# STM32MP23_CM33 register map
File version: 1.2
CPU: CM33 r0p1, little endian, MPU, FPU, vendor SysTick, 8 interrupt priority bits
Registers are 32-bit, read-write, reset 0x0 unless marked. A register's access mark holds for its fields unless they carry their own. Offsets are from the block's base; [hi:lo] are bit positions; {n}, {i} and the like mark numbered series.

## SPDIFRX — SPDIFRX address block description
Base 0x400D0000
Same registers: SPDIFRX_S 0x500D0000
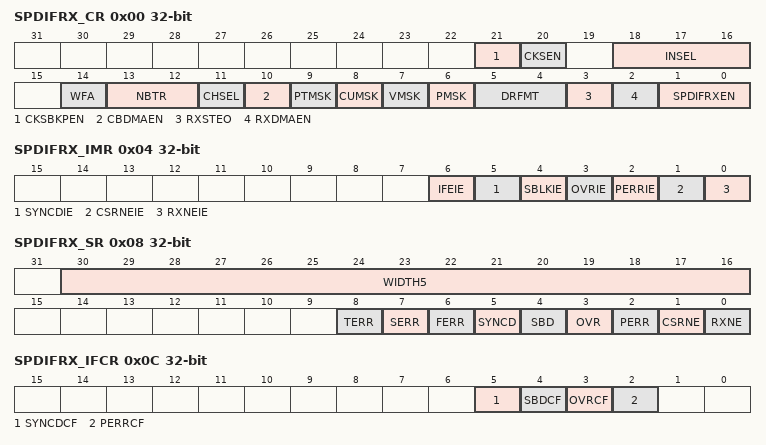
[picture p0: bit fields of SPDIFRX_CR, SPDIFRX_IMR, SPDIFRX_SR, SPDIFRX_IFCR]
0x00 SPDIFRX_CR — SPDIFRX control register
  [21] CKSBKPEN — Backup symbol clock enable This bit is set/reset by software.
    1=The SPDIFRX generates a backup symbol clock if CKSEN = 1; 0=The SPDIFRX does not generate a backup symbol clock
  [20] CKSEN — Symbol clock enable This bit is set/reset by software.
    1=The SPDIFRX generates a symbol clock; 0=The SPDIFRX does not generate a symbol clock
  [18:16] INSEL — SPDIFRX input selection other: reserved
    {v}=SPDIFRX_IN{v} selected (v=0..3)
  [14] WFA — Wait for activitysup(1)/sup This bit is set/reset by software.
    1=The SPDIFRX waits for activity on SPDIFRX_IN line (4 transitions) before performing the synchronization; 0=The SPDIFRX does not wait for activity on SPDIFRX_IN line before performing the synchronization
  [13:12] NBTR — Maximum allowed re-tries during synchronization phasesup(1)/sup
    0=No re-try is allowed (only one attempt); 1=3 re-tries allowed; 2=15 re-tries allowed; 3=63 re-tries allowed
  [11] CHSEL — Channel selectionsup(1)/sup This bit is set/reset by software.
    1=The control flow takes the channel status from channel B; 0=The control flow takes the channel status from channel A
  [10] CBDMAEN — Control buffer DMA enable for control flowsup(1)/sup This bit is set/reset by software. Note: When this bit is set, the DMA request is made whenever the CSRNE flag is set.
    1=DMA mode is enabled for reception of channel status and used data information; 0=DMA mode is disabled for reception of channel status and used data information
  [9] PTMSK — Mask of preamble type bitssup(1)/sup This bit is set/reset by software.
    1=The preamble type bits are not copied into the SPDIFRX_FMTx_DR, zeros are written instead; 0=The preamble type bits are copied into the SPDIFRX_FMTx_DR
  [8] CUMSK — Mask of channel status and user bitssup(1)/sup This bit is set/reset by software.
    1=The channel status and user bits are not copied into the SPDIFRX_FMTx_DR, zeros are written instead; 0=The channel status and user bits are copied into the SPDIFRX_FMTx_DR
  [7] VMSK — Mask of validity bitsup(1)/sup This bit is set/reset by software.
    1=The validity bit is not copied into the SPDIFRX_FMTx_DR, a zero is written instead; 0=The validity bit is copied into the SPDIFRX_FMTx_DR
  [6] PMSK — Mask parity error bitsup(1)/sup This bit is set/reset by software.
    1=The parity error bit is not copied into the SPDIFRX_FMTx_DR, a zero is written instead; 0=The parity error bit is copied into the SPDIFRX_FMTx_DR
  [5:4] DRFMT — RX data formatsup(1)/sup This bit is set/reset by software.
    2=Data sample are packed by setting two 16-bit sample into a 32-bit word; 1=Data samples are aligned in the left (MSB); 0=Data samples are aligned in the right (LSB)
  [3] RXSTEO — Stereo modesup(1)/sup This bit is set/reset by software. Note: This bit is used in case of overrun situation in order to handle misalignment.
    1=The peripheral is in stereo mode; 0=The peripheral is in mono mode
  [2] RXDMAEN — Receiver DMA enable for data flowsup(1)/sup This bit is set/reset by software. Note: When this bit is set, the DMA request is made whenever the RXNE flag is set.
    1=DMA mode is enabled for reception; 0=DMA mode is disabled for reception
  [1:0] SPDIFRXEN — Peripheral block enablesup(1)/sup This field is modified by software. It must be used to change the peripheral phase among the three possible states: STATE_IDLE, STATE_SYNC and STATE_RCV. It is not possible to transition from STATE_RCV to STATE_SYNC, the user must first go the STATE_IDLE. Note: it is possible to transition from STATE_IDLE to STATE_RCV: in that case the peripheral transitions from STATE_IDLE to STATE_SYNC and as soon as the synchronization is performed goes to STATE_RCV.
    0=Disable SPDIFRX (STATE_IDLE); 1=Enable SPDIFRX synchronization only; 3=Enable SPDIF receiver
0x04 SPDIFRX_IMR — SPDIFRX interrupt mask register
  [6] IFEIE — Serial interface error interrupt enable This bit is set and cleared by software.
    0=Interrupt is inhibited; 1=A SPDIFRX interface interrupt is generated whenever SERR = 1, TERR = 1, or FERR = 1 in theSPDIFRX_SR register
  [5] SYNCDIE — Synchronization done This bit is set and cleared by software.
    0=Interrupt is inhibited; 1=A SPDIFRX interface interrupt is generated whenever SYNCD = 1 in the SPDIFRX_SR register
  [4] SBLKIE — Synchronization block detected interrupt enable This bit is set and cleared by software.
    0=Interrupt is inhibited; 1=A SPDIFRX interface interrupt is generated whenever SBD = 1 in the SPDIFRX_SR register
  [3] OVRIE — Overrun error interrupt enable This bit is set and cleared by software.
    0=Interrupt is inhibited; 1=A SPDIFRX interface interrupt is generated whenever OVR=1 in the SPDIFRX_SR register
  [2] PERRIE — Parity error interrupt enable This bit is set and cleared by software.
    0=Interrupt is inhibited; 1=A SPDIFRX interface interrupt is generated whenever PERR=1 in the SPDIFRX_SR register
  [1] CSRNEIE — Control buffer ready interrupt enable This bit is set and cleared by software.
    0=Interrupt is inhibited; 1=A SPDIFRX interface interrupt is generated whenever CSRNE = 1 in the SPDIFRX_SR register
  [0] RXNEIE — RXNE interrupt enable This bit is set and cleared by software.
    0=Interrupt is inhibited; 1=A SPDIFRX interface interrupt is generated whenever RXNE=1 in the SPDIFRX_SR register
0x08 SPDIFRX_SR ro — SPDIFRX status register
  [30:16] WIDTH5 — duration of 5 symbols counted with spdifrx_ker_ck This value represents the amount of spdifrx_ker_ck clock periods contained on a length of 5 consecutive symbols. This value can be used to estimate the S/PDIF symbol rate. Its accuracy is limited by the frequency of spdifrx_ker_ck. For example if the spdifrx_ker_ck is fixed to 84 MHz, and WIDTH5 = 147d. The estimated sampling rate of the S/PDIF stream is: Fs = 5 x Fsubspdifrx_ker_ck/sub / (WIDTH5 x 64) ~ 44.6 kHz, so the closest standard sampling rate is 44.1kHz. Note that WIDTH5 is updated by the hardware when SYNCD goes high, and then every frame.
  [8] TERR — Time-out error This bit is set by hardware when the counter TRCNT reaches its max value. It indicates that the time interval between two transitions is too long. It generally indicates that there is no valid signal on SPDIFRX_IN input. This flag is cleared by writing SPDIFRXEN to 0. An interrupt is generated if IFEIE=1 in the SPDIFRX_IMR register.
    0=No sequence error is detected; 1=Sequence error is detected
  [7] SERR — Synchronization error This bit is set by hardware when the synchronization fails due to amount of re-tries for NBTR. This flag is cleared by writing SPDIFRXEN to 0. An interrupt is generated if IFEIE = 1 in the SPDIFRX_IMR register.
    0=No synchronization error is detected; 1=Synchronization error is detected
  [6] FERR — Framing error This bit is set by hardware when an error occurs during data reception: such as preamble not at the expected place, short transition not grouped by pairs. This is set by the hardware only if the synchronization is completed (SYNCD = 1). This flag is cleared by writing SPDIFRXEN to 0. An interrupt is generated if IFEIE=1 in the SPDIFRX_IMR register.
    0=No Manchester violation detected; 1=Manchester violation detected
  [5] SYNCD — Synchronization done This bit is set by hardware when the initial synchronization phase is properly completed. This flag is cleared by writing a 1 to its corresponding bit on SPDIFRX_IFCR register. An interrupt is generated if SYNCDIE = 1 in the SPDIFRX_IMR register.
    0=Synchronization is pending; 1=Synchronization is completed
  [4] SBD — Synchronization block detected This bit is set by hardware when a “B” preamble is detected. This flag is cleared by writing a 1 to its corresponding bit on SPDIFRX_IFCR register. An interrupt is generated if SBLKIE = 1 in the SPDIFRX_IMR register.
    0=No “B” preamble is detected; 1=“B” preamble is detected
  [3] OVR — Overrun error This bit is set by hardware when a received data is ready to be transferred in the SPDIFRX_FMTx_DR register while RXNE = 1 and both SPDIFRX_FMTx_DR and RX_BUF are full. This flag is cleared by writing a 1 to its corresponding bit on SPDIFRX_IFCR register. An interrupt is generated if OVRIE=1 in the SPDIFRX_IMR register. Note: When this bit is set, the SPDIFRX_FMTx_DR register content is not lost but the last data received are.
    0=No overrun error; 1=Overrun error is detected
  [2] PERR — Parity error This bit is set by hardware when the data and status bits of the sub-frame received contain an odd number of 0 and 1. This flag is cleared by writing a 1 to its corresponding bit on SPDIFRX_IFCR register. An interrupt is generated if PIE=1 in the SPDIFRX_IMR register.
    0=No parity error; 1=Parity error
  [1] CSRNE — Control buffer register not empty This bit is set by hardware when a valid control information is ready. This flag is cleared when reading SPDIFRX_CSR register. An interrupt is generated if CBRDYIE = 1 in the SPDIFRX_IMR register.
    0=No control word available on SPDIFRX_CSR register; 1=A control word is available on SPDIFRX_CSR register
  [0] RXNE — Read data register not empty This bit is set by hardware when a valid data is available into SPDIFRX_FMTx_DR register. This flag is cleared by reading the SPDIFRX_FMTx_DR register. An interrupt is generated if RXNEIE=1 in the SPDIFRX_IMR register.
    0=Data is not received; 1=Received data is ready to be read
0x0C SPDIFRX_IFCR wo — SPDIFRX interrupt flag clear register
  [5] SYNCDCF — clears the synchronization done flag Writing 1 in this bit clears the flag SYNCD in the SPDIFRX_SR register. Reading this bit always returns the value 0.
  [4] SBDCF — clears the synchronization block detected flag Writing 1 in this bit clears the flag SBD in the SPDIFRX_SR register. Reading this bit always returns the value 0.
  [3] OVRCF — clears the overrun error flag Writing 1 in this bit clears the flag OVR in the SPDIFRX_SR register. Reading this bit always returns the value 0.
  [2] PERRCF — clears the parity error flag Writing 1 in this bit clears the flag PERR in the SPDIFRX_SR register. Reading this bit always returns the value 0.
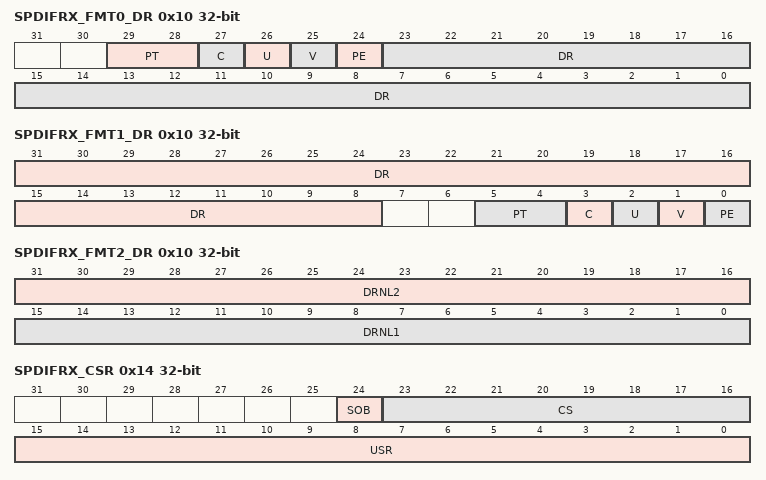
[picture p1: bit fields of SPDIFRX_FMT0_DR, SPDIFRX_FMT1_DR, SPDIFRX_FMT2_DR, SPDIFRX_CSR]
0x10 SPDIFRX_FMT0_DR ro — SPDIFRX data input register
  [29:28] PT — preamble type These bits indicate the preamble received. Note that if PTMSK = 1, this field is forced to zero
    1=Preamble B received; 2=Preamble M received; 3=Preamble W received
  [27] C — channel status bit Contains the received channel status bit, if CUMSK = 0, otherwise it is forced to 0
  [26] U — user bit Contains the received user bit, if CUMSK = 0, otherwise it is forced to 0
  [25] V — validity bit Contains the received validity bit if VMSK = 0, otherwise it is forced to 0
  [24] PE — parity error bit Contains a copy of PERR bit if PMSK = 0, otherwise it is forced to 0
  [23:0] DR — data value Contains the 24 received data bits, aligned on D[23]
0x10 SPDIFRX_FMT1_DR ro (alternate view of SPDIFRX_FMT0_DR) — SPDIFRX data input register
  [31:8] DR — data value Contains the 24 received data bits, aligned on D[23]
  [5:4] PT — preamble type These bits indicate the preamble received. Note that if PTMSK = 1, this field is forced to zero
    1=preamble B received; 2=preamble M received; 3=preamble W received
  [3] C — channel Status bit Contains the received channel status bit, if CUMSK = 0, otherwise it is forced to 0
  [2] U — user bit Contains the received user bit, if CUMSK = 0, otherwise it is forced to 0
  [1] V — validity bit Contains the received validity bit if VMSK = 0, otherwise it is forced to 0
  [0] PE — parity error bit Contains a copy of PERR bit if PMSK = 0, otherwise it is forced to 0
0x10 SPDIFRX_FMT2_DR ro (alternate view of SPDIFRX_FMT0_DR) — SPDIFRX data input register
  [31:16] DRNL2 — data value This field contains the channel A
  [15:0] DRNL1 — data value This field contains the channel B
0x14 SPDIFRX_CSR ro — SPDIFRX channel status register
  [24] SOB — start of block This bit indicates if the bit CS[0] corresponds to the first bit of a new block
    0=CS[0] is not the first bit of a new block; 1=CS[0] is the first bit of a new block
  [23:16] CS — channel A status information Bit CS[0] is the oldest value
  [15:0] USR — user data information Bit USR[0] is the oldest value, and comes from channel A, USR[1] comes channel B. So USR[n] bits come from channel A is n is even, otherwise they come from channel B.
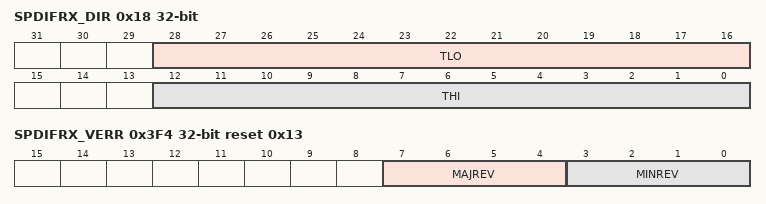
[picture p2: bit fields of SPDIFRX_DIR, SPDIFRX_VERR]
0x18 SPDIFRX_DIR ro — SPDIFRX debug information register
  [28:16] TLO — threshold LOW (TLO = 1.5 x UI / Tsubspdifrx_ker_ck/sub) This field contains the current threshold LOW estimation. This value can be used to estimate the sampling rate of the received stream. The accuracy of TLO is limited to a period of the spdifrx_ker_ck. The sampling rate can be estimated as follow: Sampling Rate = [2 x TLO x Tsubspdifrx_ker_ck /sub+/- Tsubspdifrx_ker_ck/sub] x 2/3 Note that TLO is updated by the hardware when SYNCD goes high, and then every frame.
  [12:0] THI — threshold HIGH (THI = 2.5 x UI / Tsubspdifrx_ker_ck/sub) This field contains the current threshold HIGH estimation. This value can be used to estimate the sampling rate of the received stream. The accuracy of THI is limited to a period of the spdifrx_ker_ck. The sampling rate can be estimated as follow: Sampling Rate = [2 x THI x Tsubspdifrx_ker_ck /sub+/- Tsubspdifrx_ker_ck/sub] x 2/5 Note that THI is updated by the hardware when SYNCD goes high, and then every frame.
0x3F4 SPDIFRX_VERR ro reset 0x13 — SPDIFRX version register
  [7:4] MAJREV — SPDIFRX major revision
  [3:0] MINREV — SPDIFRX minor revision
0x3F8 SPDIFRX_IPIDR ro reset 0x130041 — SPDIFRX identification register
  [31:0] ID — SPDIFRX identifier
0x3FC SPDIFRX_SIDR ro reset 0xA3C5DD01 — SPDIFRX size identification register
  [31:0] SID — Size identification These bits return the size of the memory region allocated to SPDIFRX registers. The size of this memory region is of 1Kbyte.
